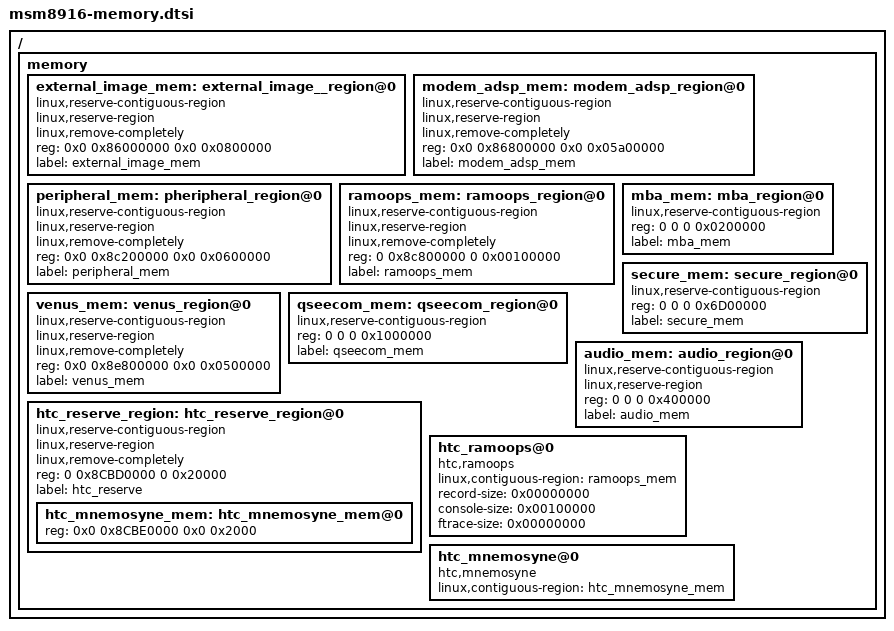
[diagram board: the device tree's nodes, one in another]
/* Copyright (c) 2014, The Linux Foundation. All rights reserved.
 *
 * This program is free software; you can redistribute it and/or modify
 * it under the terms of the GNU General Public License version 2 and
 * only version 2 as published by the Free Software Foundation.
 *
 * This program is distributed in the hope that it will be useful,
 * but WITHOUT ANY WARRANTY; without even the implied warranty of
 * MERCHANTABILITY or FITNESS FOR A PARTICULAR PURPOSE.  See the
 * GNU General Public License for more details.
 */

#include "msm8916-ion.dtsi"

/ {
	memory {
		#address-cells = <2>;
		#size-cells = <2>;

		external_image_mem: external_image__region@0 {
			linux,reserve-contiguous-region;
			linux,reserve-region;
			linux,remove-completely;
			reg = <0x0 0x86000000 0x0 0x0800000>;
			label = "external_image_mem";
		};

		modem_adsp_mem: modem_adsp_region@0 {
			linux,reserve-contiguous-region;
			linux,reserve-region;
			linux,remove-completely;
			reg = <0x0 0x86800000 0x0 0x05a00000>;
			label = "modem_adsp_mem";
		};

		peripheral_mem: pheripheral_region@0 {
			linux,reserve-contiguous-region;
			linux,reserve-region;
			linux,remove-completely;
			reg = <0x0 0x8c200000 0x0 0x0600000>;
			label = "peripheral_mem";
		};

        ramoops_mem: ramoops_region@0 {
                       linux,reserve-contiguous-region;
                       linux,reserve-region;
                       linux,remove-completely;
                       reg = <0 0x8c800000 0 0x00100000>; /* 1 MB */
                       label = "ramoops_mem";
        };

		mba_mem: mba_region@0 {
			linux,reserve-contiguous-region;
			reg = <0 0 0 0x0200000>;
			label = "mba_mem";
		};

		secure_mem: secure_region@0 {
			linux,reserve-contiguous-region;
			reg = <0 0 0 0x6D00000>;
			label = "secure_mem";
		};

                venus_mem: venus_region@0 {
                        linux,reserve-contiguous-region;
                        linux,reserve-region;
                        linux,remove-completely;
                        reg = <0x0 0x8e800000 0x0 0x0500000>;
                        label = "venus_mem";
                };

		qseecom_mem: qseecom_region@0 {
			linux,reserve-contiguous-region;
                        reg = <0 0 0 0x1000000>;
                        label = "qseecom_mem";
		};

		audio_mem: audio_region@0 {
			linux,reserve-contiguous-region;
			linux,reserve-region;
			reg = <0 0 0 0x400000>;
			label = "audio_mem";
		};

        htc_reserve_region: htc_reserve_region@0 {
            linux,reserve-contiguous-region;
            linux,reserve-region;
            linux,remove-completely;
            reg = <0 0x8CBD0000 0 0x20000>; /* 128 KB */
            label = "htc_reserve";

            #address-cells = <2>;
            #size-cells = <2>;
            htc_mnemosyne_mem: htc_mnemosyne_mem@0 {
                reg = <0x0 0x8CBE0000 0x0 0x2000>; /* 8 KB */
            };
        };

           htc_ramoops@0 {
                       compatible = "htc,ramoops";
                       linux,contiguous-region = <&ramoops_mem>;
                       record-size = <0x00000000>;
                       console-size = <0x00100000>; /* 1 MB */
                       ftrace-size = <0x00000000>;
               };
        htc_mnemosyne@0 {
            compatible = "htc,mnemosyne";
            linux,contiguous-region = <&htc_mnemosyne_mem>;
        };

	};
};
